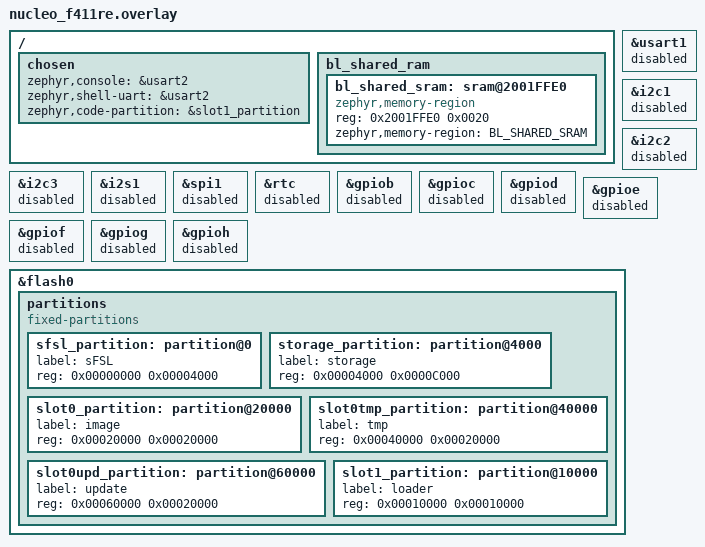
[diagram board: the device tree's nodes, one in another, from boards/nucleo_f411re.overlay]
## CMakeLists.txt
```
# SPDX-License-Identifier: Apache-2.0

cmake_minimum_required(VERSION 3.13.1)

# find_package(Zephyr) in order to load application boilerplate:
# http://docs.zephyrproject.org/application/application.html
find_package(Zephyr REQUIRED HINTS $ENV{ZEPHYR_BASE})

project(SBKshell)

zephyr_include_directories(
    ${CMAKE_CURRENT_LIST_DIR}/include
)

FILE(GLOB app_sources src/main.c)

target_sources(app PRIVATE ${app_sources})
```

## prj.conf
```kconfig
CONFIG_SBK=y
#CONFIG_SBK_MINCRYPT=y
#CONFIG_SBK_P256M=y
CONFIG_FLASH=y
CONFIG_MAIN_STACK_SIZE=4096

# Enable reboot functionality
CONFIG_REBOOT=y

# Logging
CONFIG_LOG=n
#CONFIG_SBK_LOG_LEVEL_DBG=y
#CONFIG_LOG_MODE_MINIMAL=y

# Enable uart
CONFIG_SERIAL=y
CONFIG_UART_USE_RUNTIME_CONFIGURE=n

# Disable other peripherals
CONFIG_I2C=n
CONFIG_WATCHDOG=n
CONFIG_SPI=n
CONFIG_USE_SEGGER_RTT=n
CONFIG_RTC=n

# Disable Power management
CONFIG_PM=n

# Interrupts
CONFIG_GEN_ISR_TABLES=n
CONFIG_DYNAMIC_INTERRUPTS=n
CONFIG_IRQ_OFFLOAD=n

# Kernel options
#CONFIG_SYS_CLOCK_EXISTS=n
CONFIG_MULTITHREADING=n
CONFIG_NUM_PREEMPT_PRIORITIES=0
CONFIG_KERNEL_MEM_POOL=n

# Memory protection
CONFIG_ARM_MPU=n
CONFIG_THREAD_STACK_INFO=n
CONFIG_THREAD_CUSTOM_DATA=n
CONFIG_FPU=n

# libs
CONFIG_MINIMAL_LIBC=y
CONFIG_CBPRINTF_NANO=y
CONFIG_CBPRINTF_REDUCED_INTEGRAL=y
CONFIG_CBPRINTF_LIBC_SUBSTS=y

# Boot
CONFIG_BOOT_BANNER=n

# Console
CONFIG_CONSOLE=n
CONFIG_UART_CONSOLE=n
CONFIG_STDOUT_CONSOLE=n
CONFIG_PRINTK=n
CONFIG_EARLY_CONSOLE=n

# Build
CONFIG_SIZE_OPTIMIZATIONS=y
```

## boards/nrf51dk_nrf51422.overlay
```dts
/*
 * Copyright (c) 2022 Laczen
 *
 * SPDX-License-Identifier: Apache-2.0
 */

/delete-node/ &boot_partition;
/delete-node/ &slot0_partition;
/delete-node/ &slot1_partition;
/delete-node/ &storage_partition;

/ {
	chosen {
		zephyr,code-partition = &slot1_partition;
	};
};

&flash0 {
	partitions {
		compatible = "fixed-partitions";
		#address-cells = <1>;
		#size-cells = <1>;

		sfsl_partition: partition@0 {
			label = "sFSL";
			reg = <0x00000000 0x00002000>;
		};

		storage_partition: partition@2000 {
			label = "storage";
			reg = <0x00002000 0x00005000>;
		};

		slot0_partition: partition@7000 {
			label = "image";
			reg = <0x00007000 0x00014000>;
		};

		slot0tmp_partition: partition@8000 {
			label = "tmp";
			reg = <0x00008000 0x00014000>;
		};

		slot0upd_partition: partition@1C000 {
			label = "upd";
			reg = <0x0001C000 0x00014000>;
		};

		slot1_partition: partition@30000 {
			label = "loader";
			reg = <0x00030000 0x00010000>;
		};
	};
};

/ {
	bl_shared_ram {
		#address-cells = < 0x1 >;
		#size-cells = < 0x1 >;

		bl_shared_sram: sram@20000000 {
			compatible = "zephyr,memory-region", "mmio-sram";
			reg = < 0x20000000 0x0020 >;
			zephyr,memory-region = "BL_SHARED_SRAM";
		};
	};
};
```

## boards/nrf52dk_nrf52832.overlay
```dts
/*
 * Copyright (c) 2022 Laczen
 *
 * SPDX-License-Identifier: Apache-2.0
 */

#include "../app.overlay"

/delete-node/ &boot_partition;
/delete-node/ &slot0_partition;
/delete-node/ &slot1_partition;
/delete-node/ &storage_partition;

&flash0 {
	partitions {
		compatible = "fixed-partitions";
		#address-cells = <1>;
		#size-cells = <1>;

		sfsl_partition: partition@0 {
			label = "sFSL";
			reg = <0x00000000 0x00003000>;
		};

		sldr_partition: partition@2000 {
			label = "sLDR";
			reg = <0x00003000 0x00004000>;
		};

		storage_partition: partition@7000 {
			label = "storage";
			reg = <0x00007000 0x00004000>;
		};

		image0_partition: partition@11000 {
			label = "image0";
			reg = <0x000011000 0x00037000>;
		};

		update0_partition: partition@49000 {
			label = "update0";
			reg = <0x00049000 0x00037000>;
		};

		backup0_partition: partition@48000 {
			label = "backup0";
			reg = <0x00048000 0x00037000>;
		};

	};
};

/ {
	bl_shared_ram {
		#address-cells = < 0x1 >;
		#size-cells = < 0x1 >;

		bl_shared_sram: sram@2000FFE0 {
			compatible = "zephyr,memory-region", "mmio-sram";
			reg = < 0x2000FFE0 0x0020 >;
			zephyr,memory-region = "BL_SHARED_SRAM";
		};
	};
};

&sram0 {
	reg = <0x20000000 0xFFE0>;
};
```

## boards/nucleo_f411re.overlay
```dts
/*
 * Copyright (c) 2022 Laczen
 *
 * SPDX-License-Identifier: Apache-2.0
 */

/ {
	chosen {
		zephyr,console = &usart2;
		zephyr,shell-uart = &usart2;
		zephyr,code-partition = &slot1_partition;
	};
};

&usart1 {
	status = "disabled";
};

&i2c1 {
	status = "disabled";
};

&i2c2 {
	status = "disabled";
};

&i2c3 {
	status = "disabled";
};

&i2s1 {
	status = "disabled";
};

&spi1 {
	status = "disabled";
};

&rtc {
	status = "disabled";
};

&gpiob {
	status = "disabled";
};

&gpioc {
	status = "disabled";
};

&gpiod {
	status = "disabled";
};

&gpioe {
	status = "disabled";
};

&gpiof {
	status = "disabled";
};

&gpiog {
	status = "disabled";
};

&gpioh {
	status = "disabled";
};

&flash0 {
	partitions {
		compatible = "fixed-partitions";
		#address-cells = <1>;
		#size-cells = <1>;

		sfsl_partition: partition@0 {
			label = "sFSL";
			reg = <0x00000000 0x00004000>;
		};

		storage_partition: partition@4000 {
			label = "storage";
			reg = <0x00004000 0x0000C000>;
		};

		slot0_partition: partition@20000 {
			label = "image";
			reg = <0x00020000 0x00020000>;
		};

		slot0tmp_partition: partition@40000 {
			label ="tmp";
			reg = <0x00040000 0x00020000>;
		};

		slot0upd_partition: partition@60000 {
			label ="update";
			reg = <0x00060000 0x00020000>;
		};

		slot1_partition: partition@10000 {
			label = "loader";
			reg = <0x00010000 0x00010000>;
		};
	};
};

/ {
	bl_shared_ram {
		#address-cells = < 0x1 >;
		#size-cells = < 0x1 >;

		bl_shared_sram: sram@2001FFE0 {
			compatible = "zephyr,memory-region", "mmio-sram";
			reg = < 0x2001FFE0 0x0020 >;
			zephyr,memory-region = "BL_SHARED_SRAM";
		};
	};
};
```

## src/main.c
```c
/*
 * Copyright (c) 2022 Laczen
 *
 * SPDX-License-Identifier: Apache-2.0
 */

#include <stdarg.h>
#include <string.h>
#include <stdio.h>
#include <stdlib.h>
#include <zephyr/kernel.h>
#include <zephyr/sys/reboot.h>
#include <zephyr/logging/log.h>

LOG_MODULE_REGISTER(sswpshell, LOG_LEVEL_DBG);

#include "sbk/sbk_image.h"
#include "sbk/sbk_slot.h"
#include "sbk/sbk_util.h"
#include "sbk/sbk_product.h"
#include "sbk/sbk_shell.h"

/**
 * @brief sbk_shell interface
 *
 */
int cli_cmd_reboot(const struct sbk_shell *sh, int argc, char *argv[])
{
	sbk_shell_fprintf(sh, "Rebooting\n");
	sbk_reboot();
	return 0;
}

int cli_bypass_test(const struct sbk_shell *sh, const void *data, size_t len)
{
	sbk_shell_fprintf(sh, "bypass called\r\n");
	return 1;
}

int cli_cmd_bypass(const struct sbk_shell *sh, int argc, char *argv[])
{

	if (argc < 2) {
		sbk_shell_fprintf(sh, "Insufficient arguments");
		return 0;
	}

	sbk_shell_fprintf(sh, "Going to bypass mode: ");
	sbk_shell_set_bypass(sh, cli_bypass_test);
	sbk_shell_fprintf(sh, "OK\n");
	return 0;
}

static const struct sbk_shell_cmd shell_commands[] = {
	{"reboot", cli_cmd_reboot, "Reboot the device"},
	{"bypass", cli_cmd_bypass, "Say hello"},
	{"help", sbk_shell_help_handler, "Lists all commands"},
};

SBK_SHELL_DEFINE(tst, shell_commands, 3);

int main(void)
{
	uint32_t data = 0xFF;
	char buf[80];

	LOG_INF("Welcome");
	sbk_shell_init_transport(tst);
	sbk_shell_fprintf(tst, "Welcome %x: %d\r\n", data, data);

	while (true) {
		sbk_shell_receive(tst);
	}

	return 0;
}
```
